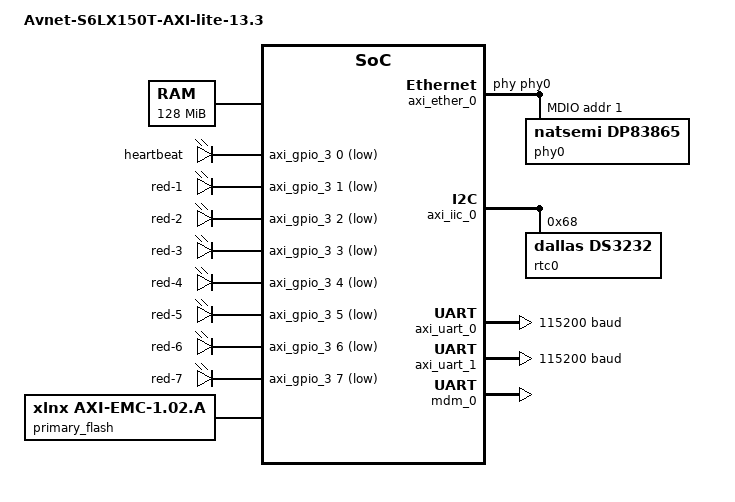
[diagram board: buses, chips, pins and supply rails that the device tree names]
/*
 * Device Tree Generator version: 1.1
 *
 * (C) Copyright 2010-2014 Li-Pro.Net
 *
 * Based on original code:
 * (C) Copyright 2007-2013 Xilinx, Inc.
 * (C) Copyright 2007-2013 Michal Simek
 * (C) Copyright 2007-2012 PetaLogix Qld Pty Ltd
 *
 * Michal SIMEK <monstr@monstr.eu>
 * Stephan Linz <linz@li-pro.net>
 *
 * This program is free software; you can redistribute it and/or
 * modify it under the terms of the GNU General Public License as
 * published by the Free Software Foundation; either version 2 of
 * the License, or (at your option) any later version.
 *
 * This program is distributed in the hope that it will be useful,
 * but WITHOUT ANY WARRANTY; without even the implied warranty of
 * MERCHANTABILITY or FITNESS FOR A PARTICULAR PURPOSE. See the
 * GNU General Public License for more details.
 *
 * You should have received a copy of the GNU General Public License
 * along with this program; if not, write to the Free Software
 * Foundation, Inc., 59 Temple Place, Suite 330, Boston,
 * MA 02111-1307 USA
 *
 * CAUTION:  This file is automatically generated by libgen.
 * Version:  Xilinx EDK 13.3 EDK_O.76xd
 * Today is: Donnerstag, the 09 of Januar, 2014; 17:09:41
 *
 * XPS project directory: Avnet-S6LX150T-AXI-lite-13.3
 */

/dts-v1/;
/ {
	#address-cells = <1>;
	#size-cells = <1>;
	compatible = "xlnx,microblaze";
	hard-reset-gpios = <&axi_gpio_0 0 1>;
	model = "Avnet-S6LX150T-AXI-lite-13.3";
	aliases {
		ethernet0 = &axi_ether_0;
		i2c0 = &axi_iic_0;
		serial0 = &axi_uart_0;
		serial1 = &axi_uart_1;
	} ;
	axi_s6_ddrx_0: memory@20000000 {
		device_type = "memory";
		reg = <0x20000000 0x8000000>;
	} ;
	chosen {
		bootargs = "console=ttyUL0,115200 ubi.mtd=2 root=ubi0:root rootfstype=ubifs rw mtdparts=ae000000.flash:16384k(bpi),4096k(kernel),11776k(rootfs),384k(u-boot-xl)ro,128k(env) debug";
		linux,stdout-path = "/axi@0/serial@89ff0000";
	} ;
	cpus {
		#address-cells = <1>;
		#cpus = <0x1>;
		#size-cells = <0>;
		microblaze_0: cpu@0 {
			bus-handle = <&axi4lite_0>;
			clock-frequency = <83333333>;
			compatible = "xlnx,microblaze-8.20.a";
			d-cache-baseaddr = <0x20000000>;
			d-cache-highaddr = <0x27ffffff>;
			d-cache-line-size = <0x10>;
			d-cache-size = <0x800>;
			device_type = "cpu";
			i-cache-baseaddr = <0x20000000>;
			i-cache-highaddr = <0x27ffffff>;
			i-cache-line-size = <0x10>;
			i-cache-size = <0x800>;
			interrupt-handle = <&axi_intc_0>;
			model = "microblaze,8.20.a";
			reg = <0>;
			timebase-frequency = <83333333>;
			xlnx,addr-tag-bits = <0x10>;
			xlnx,allow-dcache-wr = <0x1>;
			xlnx,allow-icache-wr = <0x1>;
			xlnx,area-optimized = <0x0>;
			xlnx,avoid-primitives = <0x0>;
			xlnx,branch-target-cache-size = <0x0>;
			xlnx,cache-byte-size = <0x800>;
			xlnx,d-axi = <0x1>;
			xlnx,d-lmb = <0x1>;
			xlnx,d-plb = <0x0>;
			xlnx,data-size = <0x20>;
			xlnx,dcache-addr-tag = <0x10>;
			xlnx,dcache-always-used = <0x1>;
			xlnx,dcache-byte-size = <0x800>;
			xlnx,dcache-data-width = <0x0>;
			xlnx,dcache-force-tag-lutram = <0x0>;
			xlnx,dcache-interface = <0x0>;
			xlnx,dcache-line-len = <0x4>;
			xlnx,dcache-use-fsl = <0x0>;
			xlnx,dcache-use-writeback = <0x0>;
			xlnx,dcache-victims = <0x0>;
			xlnx,debug-enabled = <0x1>;
			xlnx,div-zero-exception = <0x0>;
			xlnx,dynamic-bus-sizing = <0x1>;
			xlnx,ecc-use-ce-exception = <0x0>;
			xlnx,edge-is-positive = <0x1>;
			xlnx,endianness = <0x1>;
			xlnx,fault-tolerant = <0x0>;
			xlnx,fpu-exception = <0x0>;
			xlnx,freq = <0x4f790d5>;
			xlnx,fsl-data-size = <0x20>;
			xlnx,fsl-exception = <0x0>;
			xlnx,fsl-links = <0x0>;
			xlnx,i-axi = <0x1>;
			xlnx,i-lmb = <0x1>;
			xlnx,i-plb = <0x0>;
			xlnx,icache-always-used = <0x1>;
			xlnx,icache-data-width = <0x0>;
			xlnx,icache-force-tag-lutram = <0x0>;
			xlnx,icache-interface = <0x0>;
			xlnx,icache-line-len = <0x4>;
			xlnx,icache-streams = <0x0>;
			xlnx,icache-use-fsl = <0x0>;
			xlnx,icache-victims = <0x0>;
			xlnx,ill-opcode-exception = <0x0>;
			xlnx,instance = "microblaze_0";
			xlnx,interconnect = <0x2>;
			xlnx,interrupt-is-edge = <0x0>;
			xlnx,lockstep-slave = <0x0>;
			xlnx,mmu-dtlb-size = <0x4>;
			xlnx,mmu-itlb-size = <0x2>;
			xlnx,mmu-privileged-instr = <0x0>;
			xlnx,mmu-tlb-access = <0x3>;
			xlnx,mmu-zones = <0x2>;
			xlnx,number-of-pc-brk = <0x1>;
			xlnx,number-of-rd-addr-brk = <0x0>;
			xlnx,number-of-wr-addr-brk = <0x0>;
			xlnx,opcode-0x0-illegal = <0x0>;
			xlnx,optimization = <0x0>;
			xlnx,pvr = <0x2>;
			xlnx,pvr-user1 = <0x0>;
			xlnx,pvr-user2 = <0x0>;
			xlnx,reset-msr = <0x0>;
			xlnx,sco = <0x0>;
			xlnx,stream-interconnect = <0x0>;
			xlnx,unaligned-exceptions = <0x0>;
			xlnx,use-barrel = <0x1>;
			xlnx,use-branch-target-cache = <0x0>;
			xlnx,use-dcache = <0x1>;
			xlnx,use-div = <0x0>;
			xlnx,use-ext-brk = <0x1>;
			xlnx,use-ext-nm-brk = <0x1>;
			xlnx,use-extended-fsl-instr = <0x0>;
			xlnx,use-fpu = <0x0>;
			xlnx,use-hw-mul = <0x1>;
			xlnx,use-icache = <0x1>;
			xlnx,use-interrupt = <0x1>;
			xlnx,use-mmu = <0x3>;
			xlnx,use-msr-instr = <0x1>;
			xlnx,use-pcmp-instr = <0x1>;
			xlnx,use-stack-protection = <0x0>;
		} ;
	} ;
	axi4lite_0: axi@0 {
		#address-cells = <1>;
		#size-cells = <1>;
		compatible = "xlnx,axi-interconnect-1.04.a", "simple-bus";
		ranges ;
		axi_ether_0: ethernet@88f00000 {
			compatible = "xlnx,axi-ethernetlite-1.01.a", "xlnx,xps-ethernetlite-1.00.a";
			device_type = "network";
			interrupt-parent = <&axi_intc_0>;
			interrupts = <2 0>;
			local-mac-address = [00 0a 35 c5 ce 00];
			phy-handle = <&phy0>;
			reg = <0x88f00000 0x10000>;
			xlnx,duplex = <0x1>;
			xlnx,include-global-buffers = <0x0>;
			xlnx,include-internal-loopback = <0x0>;
			xlnx,include-mdio = <0x1>;
			xlnx,include-phy-constraints = <0x1>;
			xlnx,rx-ping-pong = <0x0>;
			xlnx,s-axi-id-width = <0x1>;
			xlnx,s-axi-supports-narrow-burst = <0x0>;
			xlnx,tx-ping-pong = <0x0>;
			mdio {
				#address-cells = <1>;
				#size-cells = <0>;
				phy0: phy@1 {
					compatible = "natsemi,dp83865";
					device_type = "ethernet-phy";
					reg = <1>;
				} ;
			} ;
		} ;
		axi_gpio_0: gpio@80ff0000 {
			#gpio-cells = <2>;
			compatible = "xlnx,axi-gpio-1.01.b", "xlnx,xps-gpio-1.00.a";
			gpio-controller ;
			reg = <0x80ff0000 0x10000>;
			xlnx,all-inputs = <0x0>;
			xlnx,all-inputs-2 = <0x0>;
			xlnx,dout-default = <0x0>;
			xlnx,dout-default-2 = <0x0>;
			xlnx,gpio-width = <0x1>;
			xlnx,gpio2-width = <0x20>;
			xlnx,interrupt-present = <0x0>;
			xlnx,is-dual = <0x0>;
			xlnx,tri-default = <0xffffffff>;
			xlnx,tri-default-2 = <0xffffffff>;
		} ;
		axi_gpio_1: gpio@80fe0000 {
			#gpio-cells = <2>;
			compatible = "xlnx,axi-gpio-1.01.b", "xlnx,xps-gpio-1.00.a";
			gpio-controller ;
			reg = <0x80fe0000 0x10000>;
			xlnx,all-inputs = <0x1>;
			xlnx,all-inputs-2 = <0x0>;
			xlnx,dout-default = <0x0>;
			xlnx,dout-default-2 = <0x0>;
			xlnx,gpio-width = <0x3>;
			xlnx,gpio2-width = <0x20>;
			xlnx,interrupt-present = <0x0>;
			xlnx,is-dual = <0x0>;
			xlnx,tri-default = <0xffffffff>;
			xlnx,tri-default-2 = <0xffffffff>;
		} ;
		axi_gpio_2: gpio@80fd0000 {
			#gpio-cells = <2>;
			compatible = "xlnx,axi-gpio-1.01.b", "xlnx,xps-gpio-1.00.a";
			gpio-controller ;
			reg = <0x80fd0000 0x10000>;
			xlnx,all-inputs = <0x1>;
			xlnx,all-inputs-2 = <0x0>;
			xlnx,dout-default = <0x0>;
			xlnx,dout-default-2 = <0x0>;
			xlnx,gpio-width = <0x8>;
			xlnx,gpio2-width = <0x20>;
			xlnx,interrupt-present = <0x0>;
			xlnx,is-dual = <0x0>;
			xlnx,tri-default = <0xffffffff>;
			xlnx,tri-default-2 = <0xffffffff>;
		} ;
		axi_gpio_3: gpio@80fc0000 {
			#gpio-cells = <2>;
			compatible = "xlnx,axi-gpio-1.01.b", "xlnx,xps-gpio-1.00.a";
			gpio-controller ;
			reg = <0x80fc0000 0x10000>;
			xlnx,all-inputs = <0x0>;
			xlnx,all-inputs-2 = <0x0>;
			xlnx,dout-default = <0x0>;
			xlnx,dout-default-2 = <0x0>;
			xlnx,gpio-width = <0x8>;
			xlnx,gpio2-width = <0x20>;
			xlnx,interrupt-present = <0x0>;
			xlnx,is-dual = <0x0>;
			xlnx,tri-default = <0xffffffff>;
			xlnx,tri-default-2 = <0xffffffff>;
		} ;
		axi_iic_0: i2c@80ef0000 {
			#address-cells = <1>;
			#size-cells = <0>;
			compatible = "xlnx,axi-iic-1.01.b", "xlnx,xps-iic-2.00.a";
			interrupt-parent = <&axi_intc_0>;
			interrupts = <5 2>;
			reg = <0x80ef0000 0x10000>;
			xlnx,gpo-width = <0x1>;
			xlnx,iic-freq = <0x186a0>;
			xlnx,scl-inertial-delay = <0x0>;
			xlnx,sda-inertial-delay = <0x0>;
			xlnx,sda-level = <0x1>;
			xlnx,ten-bit-adr = <0x0>;
			rtc0: axi-iic@68 {
				compatible = "dallas,ds3232";
				device_type = "rtc";
				interrupt-parent = <&axi_intc_0>;
				interrupts = <1 1>;
				reg = <0x68>;
			} ;
		} ;
		axi_intc_0: interrupt-controller@8aff0000 {
			#interrupt-cells = <0x2>;
			compatible = "xlnx,axi-intc-1.01.a", "xlnx,xps-intc-1.00.a";
			interrupt-controller ;
			reg = <0x8aff0000 0x10000>;
			xlnx,kind-of-intr = <0x1c>;
			xlnx,num-intr-inputs = <0x6>;
		} ;
		axi_timer_0: system-timer@8aef0000 {
			clock-frequency = <83333333>;
			compatible = "xlnx,axi-timer-1.03.a", "xlnx,xps-timer-1.00.a";
			interrupt-parent = <&axi_intc_0>;
			interrupts = <0 2>;
			reg = <0x8aef0000 0x10000>;
			xlnx,count-width = <0x20>;
			xlnx,gen0-assert = <0x1>;
			xlnx,gen1-assert = <0x1>;
			xlnx,one-timer-only = <0x0>;
			xlnx,trig0-assert = <0x1>;
			xlnx,trig1-assert = <0x1>;
		} ;
		axi_uart_0: serial@89ff0000 {
			clock-frequency = <83333333>;
			compatible = "xlnx,axi-uartlite-1.02.a", "xlnx,xps-uartlite-1.00.a";
			current-speed = <115200>;
			device_type = "serial";
			interrupt-parent = <&axi_intc_0>;
			interrupts = <3 0>;
			port-number = <0>;
			reg = <0x89ff0000 0x10000>;
			xlnx,baudrate = <0x1c200>;
			xlnx,data-bits = <0x8>;
			xlnx,odd-parity = <0x1>;
			xlnx,use-parity = <0x0>;
		} ;
		axi_uart_1: serial@89fe0000 {
			clock-frequency = <83333333>;
			compatible = "xlnx,axi-uartlite-1.02.a", "xlnx,xps-uartlite-1.00.a";
			current-speed = <115200>;
			device_type = "serial";
			interrupt-parent = <&axi_intc_0>;
			interrupts = <4 0>;
			port-number = <1>;
			reg = <0x89fe0000 0x10000>;
			xlnx,baudrate = <0x1c200>;
			xlnx,data-bits = <0x8>;
			xlnx,odd-parity = <0x1>;
			xlnx,use-parity = <0x0>;
		} ;
		gpio-leds {
			compatible = "gpio-leds";
			heartbeat {
				gpios = <&axi_gpio_3 0 1>;
				label = "heartbeat";
				linux,default-trigger = "heartbeat";
			} ;
			red-1 {
				gpios = <&axi_gpio_3 1 1>;
				label = "red-1";
			} ;
			red-2 {
				gpios = <&axi_gpio_3 2 1>;
				label = "red-2";
			} ;
			red-3 {
				gpios = <&axi_gpio_3 3 1>;
				label = "red-3";
			} ;
			red-4 {
				gpios = <&axi_gpio_3 4 1>;
				label = "red-4";
			} ;
			red-5 {
				gpios = <&axi_gpio_3 5 1>;
				label = "red-5";
			} ;
			red-6 {
				gpios = <&axi_gpio_3 6 1>;
				label = "red-6";
			} ;
			red-7 {
				gpios = <&axi_gpio_3 7 1>;
				label = "red-7";
			} ;
		} ;
		mbref_mio_0: axi-mbref-mio@80410000 {
			#address-cells = <1>;
			#size-cells = <1>;
			compatible = "xlnx,axi-mbref-mio-1.00.a", "generic-uio";
			ranges = <0x80410000 0x80410000 0x1000 0x80411000 0x80411000 0x1000 0x80412000 0x80412000 0x1000 0x80413000 0x80413000 0x1000>;
			xlnx,align-be-rdaddr = <0x0>;
			xlnx,include-timeout-cnt = <0x1>;
			xlnx,rdata-fifo-depth = <0x0>;
			xlnx,s-axi-id-width = <0x1>;
			xlnx,s-axi-supports-read = <0x1>;
			xlnx,s-axi-supports-write = <0x1>;
			xlnx,timeout-cntr-val = <0x8>;
		} ;
		mbref_reg_0: axi-mbref-reg@80800000 {
			compatible = "xlnx,axi-mbref-reg-1.00.a", "generic-uio";
			reg = <0x80800000 0x10000>;
			xlnx,dphase-timeout = <0x8>;
			xlnx,num-mem = <0x1>;
			xlnx,num-reg = <0x1>;
			xlnx,s-axi-min-size = <0x1ff>;
			xlnx,slv-awidth = <0x20>;
			xlnx,slv-dwidth = <0x20>;
			xlnx,use-wstrb = <0x0>;
		} ;
		mdm_0: serial@8fff0000 {
			compatible = "xlnx,mdm-2.00.b", "xlnx,xps-uartlite-1.00.a";
			reg = <0x8fff0000 0x10000>;
			xlnx,interconnect = <0x2>;
			xlnx,jtag-chain = <0x2>;
			xlnx,mb-dbg-ports = <0x1>;
			xlnx,use-uart = <0x1>;
		} ;
		primary_flash: flash@ae000000 {
			bank-width = <2>;
			compatible = "xlnx,axi-emc-1.02.a", "cfi-flash";
			reg = <0xae000000 0x2000000>;
			xlnx,axi-clk-period-ps = <0x2ee0>;
			xlnx,include-datawidth-matching-0 = <0x1>;
			xlnx,include-datawidth-matching-1 = <0x0>;
			xlnx,include-datawidth-matching-2 = <0x0>;
			xlnx,include-datawidth-matching-3 = <0x0>;
			xlnx,include-negedge-ioregs = <0x0>;
			xlnx,max-mem-width = <0x10>;
			xlnx,mem0-type = <0x2>;
			xlnx,mem0-width = <0x10>;
			xlnx,mem1-type = <0x0>;
			xlnx,mem1-width = <0x20>;
			xlnx,mem2-type = <0x0>;
			xlnx,mem2-width = <0x20>;
			xlnx,mem3-type = <0x0>;
			xlnx,mem3-width = <0x20>;
			xlnx,num-banks-mem = <0x1>;
			xlnx,parity-type-mem-0 = <0x0>;
			xlnx,parity-type-mem-1 = <0x0>;
			xlnx,parity-type-mem-2 = <0x0>;
			xlnx,parity-type-mem-3 = <0x0>;
			xlnx,s-axi-en-reg = <0x0>;
			xlnx,s-axi-mem-addr-width = <0x20>;
			xlnx,s-axi-mem-data-width = <0x20>;
			xlnx,s-axi-mem-id-width = <0x1>;
			xlnx,s-axi-mem-protocol = "AXI4LITE";
			xlnx,s-axi-reg-addr-width = <0x20>;
			xlnx,s-axi-reg-data-width = <0x20>;
			xlnx,s-axi-reg-protocol = "axi4";
			xlnx,synch-pipedelay-0 = <0x2>;
			xlnx,synch-pipedelay-1 = <0x2>;
			xlnx,synch-pipedelay-2 = <0x2>;
			xlnx,synch-pipedelay-3 = <0x2>;
			xlnx,tavdv-ps-mem-0 = <0x1fbd0>;
			xlnx,tavdv-ps-mem-1 = <0x3a98>;
			xlnx,tavdv-ps-mem-2 = <0x3a98>;
			xlnx,tavdv-ps-mem-3 = <0x3a98>;
			xlnx,tcedv-ps-mem-0 = <0x1fbd0>;
			xlnx,tcedv-ps-mem-1 = <0x3a98>;
			xlnx,tcedv-ps-mem-2 = <0x3a98>;
			xlnx,tcedv-ps-mem-3 = <0x3a98>;
			xlnx,thzce-ps-mem-0 = <0x88b8>;
			xlnx,thzce-ps-mem-1 = <0x1b58>;
			xlnx,thzce-ps-mem-2 = <0x1b58>;
			xlnx,thzce-ps-mem-3 = <0x1b58>;
			xlnx,thzoe-ps-mem-0 = <0x1b58>;
			xlnx,thzoe-ps-mem-1 = <0x1b58>;
			xlnx,thzoe-ps-mem-2 = <0x1b58>;
			xlnx,thzoe-ps-mem-3 = <0x1b58>;
			xlnx,tlzwe-ps-mem-0 = <0x88b8>;
			xlnx,tlzwe-ps-mem-1 = <0x0>;
			xlnx,tlzwe-ps-mem-2 = <0x0>;
			xlnx,tlzwe-ps-mem-3 = <0x0>;
			xlnx,tpacc-ps-flash-0 = <0x61a8>;
			xlnx,tpacc-ps-flash-1 = <0x61a8>;
			xlnx,tpacc-ps-flash-2 = <0x61a8>;
			xlnx,tpacc-ps-flash-3 = <0x61a8>;
			xlnx,twc-ps-mem-0 = <0x32c8>;
			xlnx,twc-ps-mem-1 = <0x3a98>;
			xlnx,twc-ps-mem-2 = <0x3a98>;
			xlnx,twc-ps-mem-3 = <0x3a98>;
			xlnx,twp-ps-mem-0 = <0x11170>;
			xlnx,twp-ps-mem-1 = <0x2ee0>;
			xlnx,twp-ps-mem-2 = <0x2ee0>;
			xlnx,twp-ps-mem-3 = <0x2ee0>;
			xlnx,twph-ps-mem-0 = <0x2ee0>;
			xlnx,twph-ps-mem-1 = <0x2ee0>;
			xlnx,twph-ps-mem-2 = <0x2ee0>;
			xlnx,twph-ps-mem-3 = <0x2ee0>;
			xlnx,wr-rec-time-mem-0 = <0x186a0>;
			xlnx,wr-rec-time-mem-1 = <0x186a0>;
			xlnx,wr-rec-time-mem-2 = <0x186a0>;
			xlnx,wr-rec-time-mem-3 = <0x186a0>;
		} ;
	} ;
} ;
